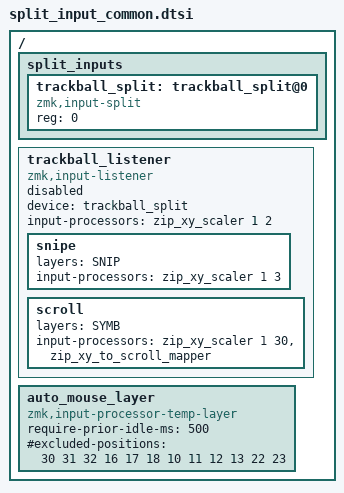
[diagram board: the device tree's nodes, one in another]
#include <dt-bindings/zmk/input_transform.h>
#include <input/processors.dtsi>

#define BASE 0
#define MOUS 1
#define SCRL 2
#define SYMB 3
#define MVNG 4
#define SNIP 5 

/ {
  split_inputs {
    #address-cells = <1>;
    #size-cells = <0>;

    trackball_split: trackball_split@0 {
      compatible = "zmk,input-split";
      reg = <0>;
    };
  };

  trackball_listener: trackball_listener {
    compatible = "zmk,input-listener";
    status = "disabled";
    device = <&trackball_split>;
     /* base processor chain on all layers
      https://zmk.dev/docs/keymaps/input-processors/scaler
      input-processors = <&zip_xy_scaler 5 5>; 
      Это сделает движения более детализированными, снизив скорость до одной трети:
      input-processors = <&zip_xy_scaler 2 6>;*/
      input-processors = <&zip_xy_scaler 1 2>;

    /* layer-5 slow-pointer override */
    snipe {
      layers = <SNIP>;
      input-processors = <&zip_xy_scaler 1 3>;
    };

    /* layer-3 scroll override 
    ПРИ ПЕРЕХОДЕ НА СЛОЙ СИМВОЛОВ АВТОМАТИЧЕСКИ ДЛЯ ТРЕКБОЛА БУДЕТ ВКЛЮЧАТЬСЯ РЕЖИМ ПРОКРУТКИ*/
    scroll {
      layers = <SYMB>;
      /*devpew
      input-processors = <&zip_xy_transform (INPUT_TRANSFORM_Y_INVERT)>, <&zip_xy_scaler 1 3>, <&zip_xy_to_scroll_mapper>;
      */
      /*280Zo*/
      input-processors = <
      //если включен параметр CONFIG_ZMK_POINTING_SMOOTH_SCROLLING, то увеличить эту цифру до 70:
            &zip_xy_scaler 1 30                        // Scales the scroll speed. одна тридцатая от скорости
            &zip_xy_to_scroll_mapper                         // Converts XY movement to scroll events
            //&zip_scroll_transform (INPUT_TRANSFORM_Y_INVERT) // Inverts the scroll direction
        >;
    };

    /* ОКЛЮЧАЮ ПЕРЕКЛЮЧЕНИЕ НА СЛОЙ МЫШИ ПРИ ДВИЖЕНИИ ТРЕКБОЛОМ
    move {
      layers = <BASE MOUS>;
      //Через СКОЛЬКО милисекунд ПОСЛЕ ОСТАНОВКИ ТРЕКБОЛА БУДЕТ ВЫКЛЮЧЕН СЛОЙ MOUSE. СТОЯЛА 1000
      input-processors = <&auto_mouse_layer MOUS 10>;
    };*/
  };

  auto_mouse_layer: auto_mouse_layer {
    compatible = "zmk,input-processor-temp-layer";
    #input-processor-cells = <2>;
    require-prior-idle-ms = <500>;
    #excluded-positions = <30 31 32 16 17 18 10 11 12 13 22 23>;
  };
};
